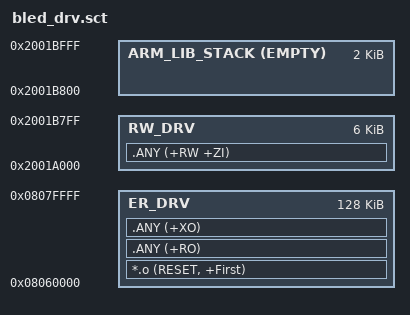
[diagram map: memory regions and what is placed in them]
; *************************************************************
; *** SVCrtOS 蓝灯驱动(BLED_DRV) 用户态分区 Scatter File     ***
; *** ROM 0x08060000，RAM 0x2001A000，与其他分区错开          ***
; *************************************************************

LR_DRV 0x08060000 0x00020000  {        ; 驱动 ROM 分区 128KB
  ER_DRV 0x08060000 0x00020000  {
   *.o (RESET, +First)                 ; DRVSTART 启动入口必须在最前
   .ANY (+RO)
   .ANY (+XO)
  }
  RW_DRV 0x2001A000 0x00001800  {      ; 驱动 RAM 6KB
   .ANY (+RW +ZI)
  }
  ARM_LIB_STACK 0x2001C000 EMPTY -0x800 {   ; 驱动栈 2KB
  }
}
